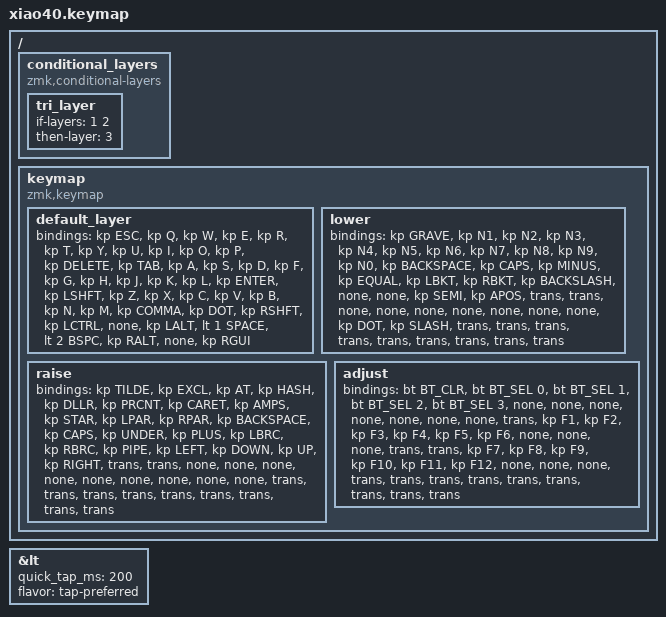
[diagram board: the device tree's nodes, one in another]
/*
 * Copyright (c) 2022 Ramon Imbao
 *
 * SPDX-License-Identifier: MIT
 */

#include <behaviors.dtsi>
#include <dt-bindings/zmk/keys.h>
#include <dt-bindings/zmk/bt.h>

&lt {
    quick_tap_ms = <200>;
    flavor = "tap-preferred";
};

/ {
    conditional_layers {
        compatible = "zmk,conditional-layers";

        tri_layer {
            if-layers = <1 2>;
            then-layer = <3>;
        };
    };

    keymap {
        compatible = "zmk,keymap";

        default_layer {
            bindings = <
 &kp ESC   &kp Q   &kp W   &kp E   &kp R   &kp T   &kp Y   &kp U   &kp I   &kp O   &kp P  &kp DELETE  &kp TAB   &kp A   &kp S   &kp D   &kp F   &kp G   &kp H   &kp J   &kp K   &kp L  &kp ENTER  &kp LSHFT   &kp Z   &kp X   &kp C   &kp V   &kp B   &kp N   &kp M  &kp COMMA  &kp DOT  &kp RSHFT  &kp LCTRL   &none  &kp LALT  &lt 1 SPACE  &lt 2 BSPC  &kp RALT   &none  &kp RGUI
            >;
        };

        lower {
            bindings = <
 &kp GRAVE  &kp N1  &kp N2  &kp N3  &kp N4  &kp N5  &kp N6  &kp N7  &kp N8  &kp N9  &kp N0  &kp BACKSPACE  &kp CAPS  &kp MINUS  &kp EQUAL  &kp LBKT  &kp RBKT  &kp BACKSLASH   &none   &none  &kp SEMI  &kp APOS  &trans  &trans   &none   &none   &none   &none   &none   &none   &none  &kp DOT  &kp SLASH  &trans  &trans  &trans  &trans  &trans  &trans  &trans  &trans  &trans
            >;
        };

        raise {
            bindings = <
 &kp TILDE  &kp EXCL  &kp AT  &kp HASH  &kp DLLR  &kp PRCNT  &kp CARET  &kp AMPS  &kp STAR  &kp LPAR  &kp RPAR  &kp BACKSPACE  &kp CAPS  &kp UNDER  &kp PLUS  &kp LBRC  &kp RBRC  &kp PIPE  &kp LEFT  &kp DOWN  &kp UP  &kp RIGHT  &trans  &trans   &none   &none   &none   &none   &none   &none   &none   &none   &none  &trans  &trans  &trans  &trans  &trans  &trans  &trans  &trans  &trans
            >;
        };

        adjust {
            bindings = <
 &bt BT_CLR  &bt BT_SEL 0  &bt BT_SEL 1  &bt BT_SEL 2  &bt BT_SEL 3   &none   &none   &none   &none   &none   &none   &none  &trans  &kp F1  &kp F2  &kp F3  &kp F4  &kp F5  &kp F6   &none   &none   &none  &trans  &trans  &kp F7  &kp F8  &kp F9  &kp F10  &kp F11  &kp F12   &none   &none   &none  &trans  &trans  &trans  &trans  &trans  &trans  &trans  &trans  &trans
            >;
        };
    };
};
